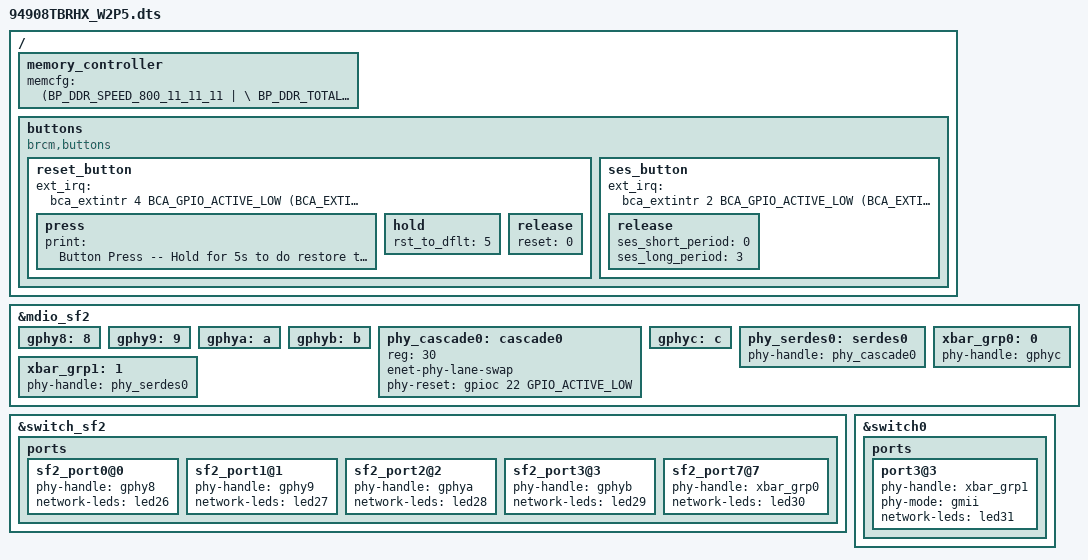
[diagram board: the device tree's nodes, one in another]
#include "4908.dtsi"
#include "94908TBRHX_leds.dtsi"

/ {
    memory_controller {
        memcfg = <(BP_DDR_SPEED_800_11_11_11 | \
                   BP_DDR_TOTAL_SIZE_1024MB  | \
                   BP_DDR_DEVICE_WIDTH_16    | \
                   BP_DDR_TOTAL_WIDTH_32BIT  | \
                   BP_DDR_SSC_CONFIG_1)>;
    };

	buttons {
		compatible = "brcm,buttons";
		reset_button {
			ext_irq = <&bca_extintr 4 BCA_GPIO_ACTIVE_LOW (BCA_EXTINTR_TYPE_LOW_LEVEL | BCA_EXTINTR_TYPE_SENSE_LEVEL)>;
			press {
				print = "Button Press -- Hold for 5s to do restore to default";
			};
			hold {
				rst_to_dflt = <5>;
			};
			release {
				reset = <0>;
			};	
		};
		ses_button {
			ext_irq = <&bca_extintr 2 BCA_GPIO_ACTIVE_LOW (BCA_EXTINTR_TYPE_LOW_LEVEL | BCA_EXTINTR_TYPE_SENSE_LEVEL)>;
			release {
				ses_short_period = <0>;
				ses_long_period = <3>;
			};
		};
	};
};

&mdio_sf2 {
	/* PHYs directly connected to SF2 */
	gphy8:8 {
		status = "okay";
	};
	gphy9:9 {
		status = "okay";
	};
	gphya:a {
		status = "okay";
	};
	gphyb:b {
		status = "okay";
	};

	/* Cascade PHY */
	phy_cascade0:cascade0 {
		reg = <30>;
		enet-phy-lane-swap;
		phy-reset = <&gpioc 22 GPIO_ACTIVE_LOW>;
		status = "okay";
	};
	
	/* PHYs connected to crossbar */
	gphyc:c {
		status = "okay";
	};
	phy_serdes0:serdes0 {
		phy-handle = <&phy_cascade0>;
		status = "okay";
	};

	/* Crossbar groups */
	xbar_grp0:0 {
		phy-handle = <&gphyc>;
		status = "okay";
	};
	xbar_grp1:1 {
		phy-handle = <&phy_serdes0>;
		status = "okay";
	};
};

&switch_sf2 {
	ports {
		sf2_port0@0 {
			phy-handle = <&gphy8>;
			network-leds = <&led26>;
			status = "okay";
		};

		sf2_port1@1 {
			phy-handle = <&gphy9>;
			network-leds = <&led27>;
			status = "okay";
		};

		sf2_port2@2 {
			phy-handle = <&gphya>;
			network-leds = <&led28>;
			status = "okay";
		};

		sf2_port3@3 {
			phy-handle = <&gphyb>;
			network-leds = <&led29>;
			status = "okay";
		};

		sf2_port7@7 {
			phy-handle = <&xbar_grp0>;
			network-leds = <&led30>;
			status = "okay";
		};

	};
};

&switch0 {
	ports {
		
		port3@3 {
			phy-handle = <&xbar_grp1>;
			phy-mode = "gmii";
			network-leds = <&led31>;
			status = "okay";
		};
	};
};
